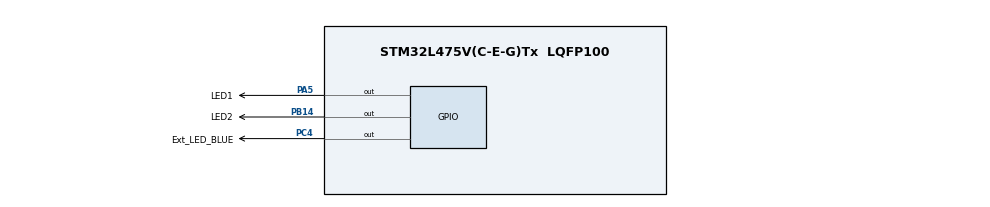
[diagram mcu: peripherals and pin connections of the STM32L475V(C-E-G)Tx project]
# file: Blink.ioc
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Mcu.Family=STM32L4
Mcu.Name=STM32L475V(C-E-G)Tx
Mcu.Package=LQFP100
NVIC.PriorityGroup=NVIC_PRIORITYGROUP_4
PA5.GPIO_Label=LED1
PA5.Signal=GPIO_Output
PB14.GPIO_Label=LED2
PB14.Signal=GPIO_Output
PC4.GPIO_Label=Ext_LED_BLUE
PC4.Signal=GPIO_Output
ProjectManager.HeapSize=0x200
ProjectManager.StackSize=0x400
ProjectManager.TargetToolchain=STM32CubeIDE
RCC.HSE_VALUE=8000000
RCC.HSI_VALUE=16000000
RCC.LSE_VALUE=32768
RCC.MSI_VALUE=4000000
RCC.VCOOutputFreq_Value=32000000
board=custom

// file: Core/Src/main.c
/* USER CODE BEGIN Header */
/**
  ******************************************************************************
  * @file           : main.c
  * @brief          : Main program body
  ******************************************************************************
  * @attention
  *
  * Copyright (c) 2022 STMicroelectronics.
  * All rights reserved.
  *
  * This software is licensed under terms that can be found in the LICENSE file
  * in the root directory of this software component.
  * If no LICENSE file comes with this software, it is provided AS-IS.
  *
  ******************************************************************************
  */
/* USER CODE END Header */
#include "main.h"

void SystemClock_Config(void);
static void MX_GPIO_Init(void);

int main(void)
{

  /* MCU Configuration--------------------------------------------------------*/

  /* Reset of all peripherals, Initializes the Flash interface and the Systick. */
  HAL_Init();

  /* Configure the system clock */
  SystemClock_Config();

  /* Initialize all configured peripherals */
  MX_GPIO_Init();

  /* Infinite loop */
  while (1)
  {

    /* USER CODE BEGIN 3 */

	// write pin state
	// NOTE: You can in turn use HAL_GPIO_TogglePin
	HAL_GPIO_TogglePin(LED1_GPIO_Port, LED1_Pin);
	HAL_GPIO_TogglePin(LED2_GPIO_Port, LED2_Pin);
	HAL_GPIO_TogglePin(Ext_LED_BLUE_GPIO_Port, Ext_LED_BLUE_Pin);
	//HAL_GPIO_TogglePin(GPIOB, GPIO_PIN_14);

	// synchronous delay for 500 ms

	HAL_Delay(500);
  }
  /* USER CODE END 3 */
}

void SystemClock_Config(void)
{
  RCC_OscInitTypeDef RCC_OscInitStruct = {0};
  RCC_ClkInitTypeDef RCC_ClkInitStruct = {0};

  /** Configure the main internal regulator output voltage
  */
  if (HAL_PWREx_ControlVoltageScaling(PWR_REGULATOR_VOLTAGE_SCALE1) != HAL_OK)
  {
    Error_Handler();
  }

  /** Initializes the RCC Oscillators according to the specified parameters
  * in the RCC_OscInitTypeDef structure.
  */
  RCC_OscInitStruct.OscillatorType = RCC_OSCILLATORTYPE_MSI;
  RCC_OscInitStruct.MSIState = RCC_MSI_ON;
  RCC_OscInitStruct.MSICalibrationValue = 0;
  RCC_OscInitStruct.MSIClockRange = RCC_MSIRANGE_6;
  RCC_OscInitStruct.PLL.PLLState = RCC_PLL_NONE;
  if (HAL_RCC_OscConfig(&RCC_OscInitStruct) != HAL_OK)
  {
    Error_Handler();
  }

  /** Initializes the CPU, AHB and APB buses clocks
  */
  RCC_ClkInitStruct.ClockType = RCC_CLOCKTYPE_HCLK|RCC_CLOCKTYPE_SYSCLK
                              |RCC_CLOCKTYPE_PCLK1|RCC_CLOCKTYPE_PCLK2;
  RCC_ClkInitStruct.SYSCLKSource = RCC_SYSCLKSOURCE_MSI;
  RCC_ClkInitStruct.AHBCLKDivider = RCC_SYSCLK_DIV1;
  RCC_ClkInitStruct.APB1CLKDivider = RCC_HCLK_DIV1;
  RCC_ClkInitStruct.APB2CLKDivider = RCC_HCLK_DIV1;

  if (HAL_RCC_ClockConfig(&RCC_ClkInitStruct, FLASH_LATENCY_0) != HAL_OK)
  {
    Error_Handler();
  }
}

static void MX_GPIO_Init(void)
{
  GPIO_InitTypeDef GPIO_InitStruct = {0};

  /* GPIO Ports Clock Enable */
  __HAL_RCC_GPIOA_CLK_ENABLE();
  __HAL_RCC_GPIOC_CLK_ENABLE();
  __HAL_RCC_GPIOB_CLK_ENABLE();

  /*Configure GPIO pin Output Level */
  HAL_GPIO_WritePin(LED1_GPIO_Port, LED1_Pin, GPIO_PIN_RESET);

  /*Configure GPIO pin Output Level */
  HAL_GPIO_WritePin(Ext_LED_BLUE_GPIO_Port, Ext_LED_BLUE_Pin, GPIO_PIN_RESET);

  /*Configure GPIO pin Output Level */
  HAL_GPIO_WritePin(LED2_GPIO_Port, LED2_Pin, GPIO_PIN_RESET);

  /*Configure GPIO pin : LED1_Pin */
  GPIO_InitStruct.Pin = LED1_Pin;
  GPIO_InitStruct.Mode = GPIO_MODE_OUTPUT_PP;
  GPIO_InitStruct.Pull = GPIO_NOPULL;
  GPIO_InitStruct.Speed = GPIO_SPEED_FREQ_LOW;
  HAL_GPIO_Init(LED1_GPIO_Port, &GPIO_InitStruct);

  /*Configure GPIO pin : Ext_LED_BLUE_Pin */
  GPIO_InitStruct.Pin = Ext_LED_BLUE_Pin;
  GPIO_InitStruct.Mode = GPIO_MODE_OUTPUT_PP;
  GPIO_InitStruct.Pull = GPIO_NOPULL;
  GPIO_InitStruct.Speed = GPIO_SPEED_FREQ_LOW;
  HAL_GPIO_Init(Ext_LED_BLUE_GPIO_Port, &GPIO_InitStruct);

  /*Configure GPIO pin : LED2_Pin */
  GPIO_InitStruct.Pin = LED2_Pin;
  GPIO_InitStruct.Mode = GPIO_MODE_OUTPUT_PP;
  GPIO_InitStruct.Pull = GPIO_NOPULL;
  GPIO_InitStruct.Speed = GPIO_SPEED_FREQ_LOW;
  HAL_GPIO_Init(LED2_GPIO_Port, &GPIO_InitStruct);

}

void Error_Handler(void)
{
  __disable_irq();
  while (1)
  {
  }
}
